# CY8C4247LQI_BL483 register map
File version: 0.1
PSoC 4200 BLE
Registers are 8-bit, read-write, no defined reset value unless marked. A register's access mark holds for its fields unless they carry their own. Offsets are from the block's base; lines under a group give offsets from that group; [hi:lo] are bit positions; {n}, {i} and the like mark numbered series; 'fields as' and 'values as' point back to an identical list; <NAME> marks a mode.

## Memory map
0x00000000 UART_1 — UART

## UART_1 — UART
Base 0x00000000
0x400F0042 TX_UART_1_TX_DATA — TX Data Register
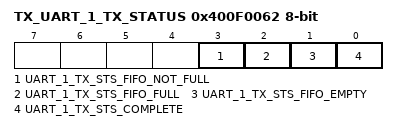
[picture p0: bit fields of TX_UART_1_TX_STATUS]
0x400F0062 TX_UART_1_TX_STATUS — TX status register
  [3] UART_1_TX_STS_FIFO_NOT_FULL ro, [2] UART_1_TX_STS_FIFO_FULL ro, [1] UART_1_TX_STS_FIFO_EMPTY ro, [0] UART_1_TX_STS_COMPLETE ro
